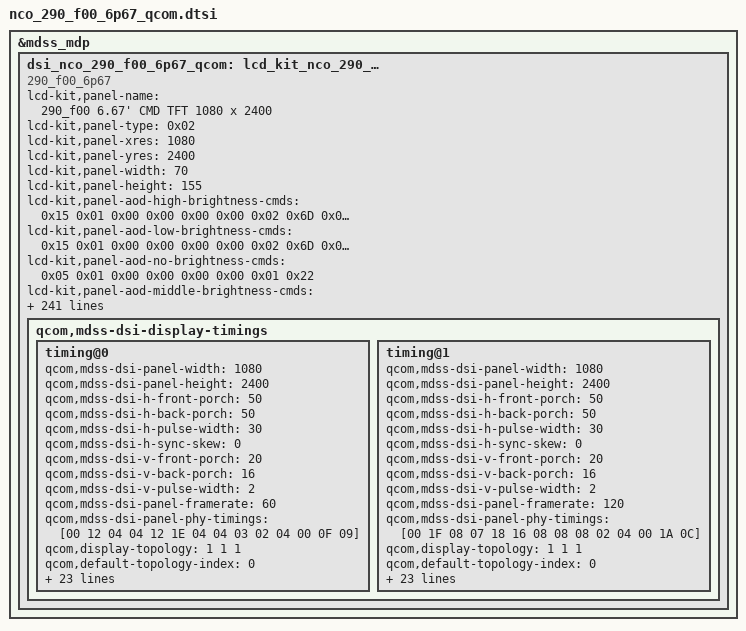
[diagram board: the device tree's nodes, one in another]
/* Copyright (c) 2013, The Linux Foundation. All rights reserved.
 *
 * This program is free software; you can redistribute it and/or modify
 * it under the terms of the GNU General Public License version 2 and
 * only version 2 as published by the Free Software Foundation.
 *
 * This program is distributed in the hope that it will be useful,
 * but WITHOUT ANY WARRANTY; without even the implied warranty of
 * MERCHANTABILITY or FITNESS FOR A PARTICULAR PURPOSE.  See the
 * GNU General Public License for more details.
 */

/*-------------------------------------------------------------------------
 * This file is autogenerated file using gcdb parser. Please do not edit it.
 * Update input XML file to add a new entry or update variable in this file
 * VERSION = 1.1
 *-----------------------------------------------------------------------*/
&mdss_mdp {
	dsi_nco_290_f00_6p67_qcom: lcd_kit_nco_290_f00_6p67_qcom {
		compatible = "290_f00_6p67";
		lcd-kit,panel-name = "290_f00 6.67' CMD TFT 1080 x 2400";
		lcd-kit,panel-type = <0x02>;
		lcd-kit,panel-xres = <1080>;
		lcd-kit,panel-yres = <2400>;
		lcd-kit,panel-width = <70>;
		lcd-kit,panel-height = <155>;
		lcd-kit,panel-aod-high-brightness-cmds = <0x15 0x01 0x00 0x00 0x00 0x00 0x02 0x6D 0x00
		0x05 0x01 0x00 0x00 0x00 0x00 0x01 0x13>;
		lcd-kit,panel-aod-low-brightness-cmds = <0x15 0x01 0x00 0x00 0x00 0x00 0x02 0x6D 0x02
		0x05 0x01 0x00 0x00 0x00 0x00 0x01 0x13>;
		lcd-kit,panel-aod-no-brightness-cmds = <0x05 0x01 0x00 0x00 0x00 0x00 0x01 0x22>;
		lcd-kit,panel-aod-middle-brightness-cmds = <0x15 0x01 0x00 0x00 0x00 0x00 0x02 0x6D 0x01
		0x05 0x01 0x00 0x00 0x00 0x00 0x01 0x13>;
		lcd-kit,pcd-check-reg-cmds = <0x82>;
		lcd-kit,check-reg-on-cmds = <0x06 0x01 0x00 0x00 0x0a 0x00 0x01 0x0a>;
		lcd-kit,check-reg-on-value = <0x9c>;
		lcd-kit,check-aod-reg-on-cmds = <0x06 0x01 0x00 0x00 0x0a 0x00 0x01 0x0a>;
		lcd-kit,check-aod-reg-on-value = <0xdc>;
		lcd-kit,check-reg-off-cmds = <0x06 0x01 0x00 0x00 0x0a 0x00 0x01 0x0a>;
		lcd-kit,check-reg-off-value = <0x08>;
		lcd-kit,check-reg-on-cmds-state = "dsi_lp_mode";
		lcd-kit,check-aod-reg-on-cmds-state = "dsi_lp_mode";
		lcd-kit,check-reg-off-cmds-state = "dsi_lp_mode";
		lcd-kit,pcd-check-reg-value = <0x82>;
		lcd-kit,pcd-errflag-check-support = <0>;
		lcd-kit,checksum-enable-cmds = <0x39 0x01 0x00 0x00 0x00 0x00 0x03 0xFF 0x5A 0x80
		0x15 0x01 0x00 0x00 0x00 0x00 0x02 0xFC 0x11>;
		lcd-kit,checksum-enable-cmds-state = "dsi_lp_mode";
		lcd-kit,checksum-disable-cmds = <0x39 0x01 0x00 0x00 0x00 0x00 0x03 0xFF 0x5A 0x80
		0x15 0x01 0x00 0x00 0x00 0x00 0x02 0xFC 0x00>;
		lcd-kit,checksum-disable-cmds-state = "dsi_lp_mode";
		lcd-kit,checksum-cmds = <0x39 0x01 0x00 0x00 0x00 0x00 0x03 0xFF 0x5A 0x80
		0x15 0x01 0x00 0x00 0x00 0x00 0x02 0x65 0x01
		0x14 0x01 0x00 0x00 0x00 0x00 0x08 0xFC 0x00 0x00 0x00 0x00 0x00 0x00 0x00>;
		lcd-kit,checksum-cmds-state = "dsi_lp_mode";
		lcd-kit,checksum-value = <0xc6 0xa1 0x3f 0x1d 0xc6 0x47 0x89 0x3a
		0x43 0x61 0xc0 0x9a 0xc3 0xe4 0x29 0xf8
		0x6c 0xbb 0x14 0x70 0xbf 0xc9 0x49 0x5c>;
		lcd-kit,hor-line-cmds = <0x15 0x01 0x00 0x00 0x00 0x00 0x02 0x6C 0x01
		0x39 0x01 0x00 0x00 0x00 0x00 0x03 0xF0 0xAA 0x16
		0x39 0x01 0x00 0x00 0x00 0x00 0x05 0xB1 0x24 0x25 0x25 0x0A
		0x39 0x01 0x00 0x00 0x00 0x00 0x05 0xB6 0x24 0x25 0x25 0x0A>;
		lcd-kit,hor-line-cmds-state = "dsi_lp_mode";
		lcd-kit,pcd-read-cmds = <0x39 0x01 0x00 0x00 0x00 0x00 0x03 0xF0 0xAA 0x12
		0x39 0x01 0x00 0x00 0x0a 0x00 0x05 0xD0 0x8D 0x01 0x01 0x00
		0x15 0x01 0x00 0x00 0x00 0x00 0x02 0x65 0x03
		0x06 0x01 0x00 0x00 0x00 0x00 0x01 0xD0>;
		lcd-kit,pcd-read-cmds-state  = "dsi_lp_mode";
		lcd-kit,vtc-line-cmds = <0x39 0x01 0x00 0x00 0x00 0x00 0x03 0x51 0x00 0x00
		0x39 0x01 0x00 0x00 0x00 0x00 0x03 0xF0 0xAA 0x10
		0x15 0x01 0x00 0x00 0x00 0x00 0x02 0xC3 0x11
		0x39 0x01 0x00 0x00 0x00 0x00 0x03 0xF0 0xAA 0x12
		0x15 0x01 0x00 0x00 0x00 0x00 0x02 0xCF 0x00
		0x39 0x01 0x00 0x00 0x00 0x00 0x0F 0xB6 0x00 0x3F 0x00 0x3F 0x00 0x3F 0x00 0x3F 0x00 0x3F 0x00 0x3F 0x00 0x3F
		0x39 0x01 0x00 0x00 0x00 0x00 0x03 0xF0 0xAA 0x13
		0x15 0x01 0x00 0x00 0x00 0x00 0x02 0x65 0x01
		0x15 0x01 0x00 0x00 0x00 0x00 0x02 0xC7 0x12
		0x15 0x01 0x00 0x00 0x00 0x00 0x02 0x65 0x01
		0x15 0x01 0x00 0x00 0x00 0x00 0x02 0xCC 0x12>;
		lcd-kit,vtc-line-cmds-state  = "dsi_lp_mode";
		lcd-kit,ddic-lv-det-enter1-cmds = <0x39 0x01 0x00 0x00 0x00 0x00 0x03 0xF0 0xAA 0x12
		0x39 0x01 0x00 0x00 0x00 0x00 0x05 0xC7 0x2F 0x43 0x32 0x44>;
		lcd-kit,ddic-lv-det-enter1-cmds-state  = "dsi_lp_mode";
		lcd-kit,ddic-lv-det-enter2-cmds = <0x39 0x01 0x00 0x00 0x00 0x00 0x03 0xF0 0xAA 0x12
		0x39 0x01 0x00 0x00 0x00 0x00 0x05 0xC7 0x2F 0x43 0x32 0x44>;
		lcd-kit,ddic-lv-det-enter2-cmds-state  = "dsi_lp_mode";
		lcd-kit,ddic-lv-det-enter3-cmds = <0x39 0x01 0x00 0x00 0x00 0x00 0x03 0xF0 0xAA 0x12
		0x39 0x01 0x00 0x00 0x00 0x00 0x05 0xC7 0x2F 0x43 0x32 0x44>;
		lcd-kit,ddic-lv-det-enter3-cmds-state  = "dsi_lp_mode";
		lcd-kit,ddic-lv-det-enter4-cmds = <0x39 0x01 0x00 0x00 0x00 0x00 0x03 0xF0 0xAA 0x12
		0x39 0x01 0x00 0x00 0x00 0x00 0x05 0xC7 0x2F 0x43 0x32 0x44>;
		lcd-kit,ddic-lv-det-enter4-cmds-state  = "dsi_lp_mode";
		lcd-kit,ddic-lv-det-rd1-cmds = <0x06 0x01 0x00 0x00 0x00 0x00 0x01 0x0a>;
		lcd-kit,ddic-lv-det-rd1-cmds-state  = "dsi_lp_mode";
		lcd-kit,ddic-lv-det-rd2-cmds = <0x06 0x01 0x00 0x00 0x00 0x00 0x01 0x0a>;
		lcd-kit,ddic-lv-det-rd2-cmds-state  = "dsi_lp_mode";
		lcd-kit,ddic-lv-det-rd3-cmds = <0x06 0x01 0x00 0x00 0x00 0x00 0x01 0x0a>;
		lcd-kit,ddic-lv-det-rd3-cmds-state  = "dsi_lp_mode";
		lcd-kit,ddic-lv-det-rd4-cmds = <0x06 0x01 0x00 0x00 0x00 0x00 0x01 0x0a>;
		lcd-kit,ddic-lv-det-rd4-cmds-state  = "dsi_lp_mode";
		lcd-kit,ddic-lv-det-value1 = <0x9c>;
		lcd-kit,ddic-lv-det-value2 = <0x9c>;
		lcd-kit,ddic-lv-det-value3 = <0x9c>;
		lcd-kit,ddic-lv-det-value4 = <0x9c>;
		lcd-kit,bl-after-frame = <0>;
		lcd-kit,cmd-async-support = <0>;
		lcd-kit,ap-aod-support = <1>;
		lcd-kit,mask-delay-time-before-fp = <33334>;
		lcd-kit,mask-delay-time-after-fp = <0>;
		lcd-kit,left-time-to-te-us = <26500>;
		lcd-kit,right-time-to-te-us = <27000>;
		lcd-kit,te-interval-time-us = <16667>;
		lcd-kit,dc-delay-support = <1>;
		lcd-kit,dc-left-time-to-te-us = <9000>;
		lcd-kit,dc-right-time-to-te-us = <10000>;
		lcd-kit,dc-delay-time-before-fp = <0>;
		lcd-kit,dc-delay-time-after-fp = <0>;
		lcd-kit,oneside-mode-support = <0>;
		lcd-kit,color-aod-detect-support = <0>;
		lcd-kit,elvdd-detect-support = <0>;
		lcd-kit,elvdd-detect-type = <2>;
		lcd-kit,elvdd-detect-value = <1>;
		lcd-kit,elvdd-delay = <50>;
		lcd-kit,elvdd-detect-gpio = <104>;
		lcd-kit,check-reg-on-support = <0>;
		lcd-kit,check-reg-on-support-dsm-report = <0>;
		lcd-kit,check-aod-reg-on-support = <0>;
		lcd-kit,check-aod-reg-on-support-dsm-report = <0>;
		lcd-kit,check-reg-off-support = <0>;
		lcd-kit,check-reg-off-support-dsm-report = <0>;
		lcd-kit,checksum-support = <1>;
		lcd-kit,pcd-cmds-support = <1>;
		lcd-kit,pcd-check-reg-value-compare-mode = <1>;
		lcd-kit,vtc-line-support = <1>;
		lcd-kit,ddic-lv-det-support = <1>;
		lcd-kit,hor-line-support = <1>;
		lcd-kit,hor-line-duration = <600>;
		lcd-kit,vtc-line-no-reset = <1>;
		qcom,mdss-dsi-panel-type = "dsi_cmd_mode";
		qcom,mdss-pan-physical-width-dimension = <70>;
		qcom,mdss-pan-physical-height-dimension = <155>;
		qcom,dsi-ctrl-num = <0>;
		qcom,dsi-phy-num = <0>;
		qcom,panel-supply-entries = <&dsi_panel_pwr_supply>;
		qcom,mdss-dsi-virtual-channel-id = <0>;
		qcom,mdss-dsi-h-sync-pulse = <0>;
		qcom,mdss-dsi-bllp-eof-power-mode;
		qcom,mdss-dsi-bllp-power-mode;
		qcom,mdss-dsi-dma-schedule-line = <1>;
		qcom,mdss-dsi-bpp = <24>;
		qcom,mdss-dsi-color-order = "rgb_swap_rgb";
		qcom,mdss-dsi-underflow-color = <0xff>;
		qcom,mdss-dsi-border-color = <0>;
		qcom,mdss-dsi-traffic-mode = "burst_mode";
		qcom,mdss-dsi-lane-map = "lane_map_0123";
		qcom,mdss-dsi-lane-0-state;
		qcom,mdss-dsi-lane-1-state;
		qcom,mdss-dsi-lane-2-state;
		qcom,mdss-dsi-lane-3-state;
		qcom,mdss-dsi-mdp-trigger = "none";
		qcom,mdss-dsi-dma-trigger = "trigger_sw";
		qcom,mdss-dsi-te-pin-select = <1>;
		qcom,mdss-dsi-wr-mem-start = <0x2c>;
		qcom,mdss-dsi-wr-mem-continue = <0x3c>;
		qcom,mdss-dsi-te-dcs-command = <1>;
		qcom,mdss-dsi-te-check-enable;
		qcom,mdss-dsi-te-using-te-pin;
		qcom,dsi-panel-gpio-address = <0x0F100000 0x1000>;
		qcom,dsi-panel-gpio-pins = <12 93 80>;
		qcom,dsi-panel-gpio-names = "reg-gpio", "reset-gpio", "platform-te-gpio";
		qcom,mdss-dsi-t-clk-post = <0>;
		qcom,mdss-dsi-t-clk-pre = <0>;
		qcom,dsi-select-clocks = "mux_byte_clk0", "mux_pixel_clk0";
		qcom,mdss-dsi-stream = <0>;
		lcd-kit,check-thread-support = <0>;
		lcd-kit,check-time-period = <5000>;
		lcd-kit,check-fold-support = <0>;
		lcd-kit,fold-low-power-support = <0>;
		lcd-kit,fold-height = <0>;
		lcd-kit,unfold-height = <0>;
		lcd-kit,power-support = <0>;
		lcd-kit,three-stage-poweron = <1>;
		lcd-kit,fold-lp-time = <0>;
		lcd-kit,fold-nolp-time = <0>;
		qcom,sublinks-count = <2>;
		qcom,lanes-per-sublink = <2>;
		qcom,mdss-dsi-panel-hdr-color-primaries = <14500 15500 32000 17000 15500 30000 8000 3000>;
		qcom,mdss-dsi-panel-peak-brightness = <4200000>;
		qcom,mdss-dsi-panel-blackness-level = <3230>;
		qcom,dynamic-mode-switch-enabled;
		qcom,dynamic-mode-switch-type = "dynamic-resolution-switch-immediate";
		qcom,mdss-dsi-bl-pmic-control-type = "bl_ctrl_dcs";
		qcom,mdss-dsi-bl-min-level = <1>;
		qcom,mdss-dsi-bl-max-level = <10000>;
		qcom,esd-check-enabled;
		qcom,mdss-dsi-panel-status-command = [06 01 00 00 00 00 02 68 00
			06 01 00 00 00 00 01 0A
			39 01 00 00 00 00 03 FF 5A 80
			15 01 00 00 00 00 02 65 37
			06 01 00 00 00 00 03 F5 00 00
			39 01 00 00 00 00 03 F0 AA 10
			06 01 00 00 00 00 02 ED 00
			39 01 00 00 00 00 03 FF 5A 80
			06 01 00 00 00 00 09 FE 00 00 00 00 00 00 00 00];
		qcom,mdss-dsi-panel-status-command-state = "dsi_lp_mode";
		qcom,mdss-dsi-panel-status-check-mode = "reg_read";
		qcom,mdss-dsi-panel-status-read-length = <2 1 0 0 3 0 2 0 9>;
		qcom,mdss-dsi-panel-status-value = <0x00 0x00>,<0x9C>,<0x00 0x00 0x00>,<0x00 0x30>,<0x00 0x00 0x00 0x00 0x00 0x00 0x00 0x00 0x00>;
		lcd-kit,power-on-stage = <2 1 3
				1 1 3
				9 1 12>;
		lcd-kit,lp-on-stage = <5 1 5
				5 0 2
				5 1 30
				7 1 0
				6 1 0
				8 1 0>;
		lcd-kit,lp-off-stage = <0 0 0>;
		lcd-kit,power-off-stage = <7 0 0
				6 0 0
				8 0 0
				5 0 2
				9 0 2
				1 0 2
				2 0 1>;
		lcd-kit,only-power-off-stage = <0 0 0>;
		lcd-kit,pt-support = <1>;
		lcd-kit,panel-on-always-reset = <0>;
		lcd-kit,lcd-vci = <1 13 3000000 3000000 3000000 10000 80>;
		lcd-kit,lcd-iovcc = <1 12 1800000 1800000 1800000 60700 80>;
		lcd-kit,lcd-vdd = <1 16 1250000 1250000 1250000 30000 80>;
		lcd-kit,lcd-reset = <2 93 0>;
		lcd-kit,lcd-vci-name = "vdd";
		lcd-kit,lcd-iovcc-name = "vddio";
		lcd-kit,lcd-vdd-name = "ddic";
		lcd-kit,project-id-support = <0>;
		lcd-kit,default-project-id = "B2359S2920";
		lcd-kit,sn-code-support = <1>;
		lcd-kit,oem-info-support = <1>;
		lcd-kit,oem-barcode-2d-support = <1>;
		lcd-kit,oem-barcode-2d-num-offset = <0>;
		lcd-kit,barcode-2d-cmds = <0x39 0x01 0x00 0x00 0x00 0x00 0x03 0xF0 0xAA 0x10
		0x14 0x01 0x00 0x00 0x00 0x00 0x15 0xC8 0x00 0x00 0x00 0x00 0x00 0x00 0x00 0x00 0x00 0x00 0x00 0x00 0x00 0x00 0x00 0x00 0x00 0x00 0x00 0x00>;
		lcd-kit,barcode-2d-cmds-state = "dsi_lp_mode";
		lcd-kit,panel-getblmaxnit-type = <0>;
		lcd-kit,panel-blmaxnit-min-value = <400>;
		lcd-kit,inversion-support = <0>;
		lcd-kit,panel-gpio-offset = <336>;
		lcd-kit,finger-unlock-state-support = <0>;
		lcd-kit,finger-handle-esd-support = <1>;
		lcd-kit,esd-reg-te-check = <0>;
		lcd-kit,dump-support = <0>;
		lcd-kit,underflow-support = <1>;
		lcd-kit,panel-bl-max-nit = <450>;
		lcd-kit,panel-bl-min = <3>;
		lcd-kit,panel-bl-max = <10000>;
		lcd-kit,panel-bl-def = <2047>;
		lcd-kit,check-reg-support = <0>;
		lcd-kit,thp-proximity-support = <0>;
		lcd-kit,proximity-reset-delay-min = <65>;
		lcd-kit,backlight-cmds = <0x39 0x01 0x00 0x00 0x00 0x00 0x03 0x51 0x00 0x00>;
		lcd-kit,backlight-cmds-state = "dsi_lp_mode";
		lcd-kit,backlight-order = <0>;
		lcd-kit,backlight-need-sync = <0>;
		lcd-kit,fps-support = <1>;
		lcd-kit,default-fps = <60>;
		lcd-kit,panel-support-fps-list = <60 120>;
		lcd-kit,fps-60-cmd = "vndservice call display.qservice 25 i32 0 i32 0";
		lcd-kit,fps-90-cmd = "vndservice call display.qservice 25 i32 2 i32 0";
		lcd-kit,fps-120-cmd = "vndservice call display.qservice 25 i32 1 i32 0";
		qcom,mdss-dsi-display-timings {
			timing@0 {
				qcom,mdss-dsi-panel-width = <1080>;
				qcom,mdss-dsi-panel-height = <2400>;
				qcom,mdss-dsi-h-front-porch = <50>;
				qcom,mdss-dsi-h-back-porch = <50>;
				qcom,mdss-dsi-h-pulse-width = <30>;
				qcom,mdss-dsi-h-sync-skew = <0>;
				qcom,mdss-dsi-v-front-porch = <20>;
				qcom,mdss-dsi-v-back-porch = <16>;
				qcom,mdss-dsi-v-pulse-width = <2>;
				qcom,mdss-dsi-panel-framerate = <60>;
				qcom,mdss-dsi-panel-phy-timings= [00 12 04 04 12 1E 04
			04 03 02 04 00 0F 09];
				qcom,display-topology  = <1 1 1>;
				qcom,default-topology-index  = <0>;
				qcom,mdss-dsi-on-command = [15 01 00 00 00 00 02 03 01
		15 01 00 00 00 00 02 35 00
		15 01 00 00 00 00 02 53 20
		15 01 00 00 00 00 02 59 09
		15 01 00 00 00 00 02 6C 00
		15 01 00 00 00 00 02 6F 02
		39 01 00 00 00 00 15 70 11 00 00 AB 30 80 09 60 04 38 00 28 04 38 04 38 02 00 03 1C
		15 01 00 00 00 00 02 65 14
		39 01 00 00 00 00 15 70 00 20 05 2D 00 0F 00 0C 02 77 01 46 18 00 10 F0 07 10 20 00
		15 01 00 00 00 00 02 65 28
		39 01 00 00 00 00 15 70 06 0F 0F 33 0E 1C 2A 38 46 54 62 69 70 77 79 7B 7D 7E 02 02
		15 01 00 00 00 00 02 65 3C
		39 01 00 00 00 00 15 70 22 00 2A 40 2A BE 3A FC 3A FA 3A F8 3B 38 3B 78 3B B6 4B B6
		15 01 00 00 00 00 02 65 50
		39 01 00 00 00 00 0F 70 4B F4 4B F4 6C 34 84 74 00 00 00 00 00 00
		39 01 00 00 00 00 03 F0 AA 10
		15 01 00 00 00 00 02 B3 C7
		15 01 00 00 00 00 02 B6 00
		39 01 00 00 00 00 15 D0 84 15 50 14 20 00 29 4B 17 4F 22 00 4B 29 00 00 00 00 05 05
		15 01 00 00 00 00 02 65 01
		39 01 00 00 00 00 04 EB 03 30 01
		39 01 00 00 00 00 03 F0 AA 12
		39 01 00 00 00 00 05 C7 2E 73 32 74
		39 01 00 00 00 00 03 F0 AA 14
		39 01 00 00 00 00 03 B2 03 33
		39 01 00 00 00 00 0D B4 0A 49 00 00 0A 49 00 00 0A 49 00 00
		39 01 00 00 00 00 0A B5 00 18 18 18 18 18 18 06 01
		39 01 00 00 00 00 07 B9 00 00 0A 18 18 18
		39 01 00 00 00 00 0D BC 10 00 00 0A 11 18 68 18 68 18 68 00
		39 01 00 00 00 00 0D BE 10 10 00 0A 22 18 45 18 45 18 45 00
		39 01 00 00 00 00 03 F0 AA 15
		15 01 00 00 00 00 02 BD 22
		39 01 00 00 00 00 03 FF 5A 81
		15 01 00 00 00 00 02 65 05
		15 01 00 00 00 00 02 F3 0F
		15 01 00 00 00 00 02 65 01
		15 01 00 00 00 00 02 F4 9A
		39 01 00 00 00 00 03 FF 5A 80
		15 01 00 00 00 00 02 65 13
		15 01 00 00 00 00 02 FD 01
		39 01 00 00 00 00 03 FF 5A 82
		15 01 00 00 00 00 02 F9 00
		39 01 00 00 00 00 03 FF 5A 83
		15 01 00 00 00 00 02 65 04
		15 01 00 00 00 00 02 F8 00
		39 01 00 00 00 00 03 F0 AA 00
		39 01 00 00 00 00 03 FF 5A 00
		05 01 00 00 78 00 01 11
		05 01 00 00 00 00 01 29
		39 01 00 00 00 00 03 F0 AA 10
		15 01 00 00 00 00 02 65 03
		15 01 00 00 0A 00 02 EB 09];
				qcom,mdss-dsi-on-command-state = "dsi_lp_mode";
				qcom,mdss-dsi-off-command = [05 01 00 00 0a 00 01 28
		05 01 00 00 78 00 01 10];
				qcom,mdss-dsi-off-command-state = "dsi_lp_mode";
				qcom,compression-mode = "dsc";
				qcom,mdss-dsc-slice-height = <40>;
				qcom,mdss-dsc-slice-width = <1080>;
				qcom,mdss-dsc-slice-per-pkt = <1>;
				qcom,mdss-dsc-bit-per-component = <10>;
				qcom,mdss-dsc-bit-per-pixel = <8>;
				qcom,mdss-dsc-block-prediction-enable;
				qcom,mdss-dsi-timing-switch-command = [15 01 00 00 11 00 02 6C 00];
				qcom,mdss-dsi-timing-switch-command-state = "dsi_lp_mode";
				qcom,mdss-dsi-lp1-command = [05 01 00 00 00 00 01 22
		05 01 00 00 00 00 01 39
		39 01 00 00 00 00 03 F0 AA 10
		15 01 00 00 00 00 02 B3 C6];
				qcom,mdss-dsi-lp1-command-state = "dsi_lp_mode";
				qcom,mdss-dsi-nolp-command = [05 01 00 00 00 00 01 22
		05 01 00 00 00 00 01 38
		39 01 00 00 00 00 03 F0 AA 10
		15 01 00 00 32 00 02 B3 C7
		05 01 00 00 00 00 01 13];
				qcom,mdss-dsi-nolp-command-state = "dsi_lp_mode";
			};
			timing@1 {
				qcom,mdss-dsi-panel-width = <1080>;
				qcom,mdss-dsi-panel-height = <2400>;
				qcom,mdss-dsi-h-front-porch = <50>;
				qcom,mdss-dsi-h-back-porch = <50>;
				qcom,mdss-dsi-h-pulse-width = <30>;
				qcom,mdss-dsi-h-sync-skew = <0>;
				qcom,mdss-dsi-v-front-porch = <20>;
				qcom,mdss-dsi-v-back-porch = <16>;
				qcom,mdss-dsi-v-pulse-width = <2>;
				qcom,mdss-dsi-panel-framerate = <120>;
				qcom,mdss-dsi-panel-phy-timings= [00 1F 08 07 18 16 08
			08 08 02 04 00 1A 0C];
				qcom,display-topology  = <1 1 1>;
				qcom,default-topology-index  = <0>;
				qcom,mdss-dsi-on-command = [15 01 00 00 00 00 02 03 01
		15 01 00 00 00 00 02 35 00
		15 01 00 00 00 00 02 53 20
		15 01 00 00 00 00 02 59 09
		15 01 00 00 00 00 02 6C 01
		15 01 00 00 00 00 02 6F 02
		39 01 00 00 00 00 15 70 11 00 00 AB 30 80 09 60 04 38 00 28 04 38 04 38 02 00 03 1C
		15 01 00 00 00 00 02 65 14
		39 01 00 00 00 00 15 70 00 20 05 2D 00 0F 00 0C 02 77 01 46 18 00 10 F0 07 10 20 00
		15 01 00 00 00 00 02 65 28
		39 01 00 00 00 00 15 70 06 0F 0F 33 0E 1C 2A 38 46 54 62 69 70 77 79 7B 7D 7E 02 02
		15 01 00 00 00 00 02 65 3C
		39 01 00 00 00 00 15 70 22 00 2A 40 2A BE 3A FC 3A FA 3A F8 3B 38 3B 78 3B B6 4B B6
		15 01 00 00 00 00 02 65 50
		39 01 00 00 00 00 0F 70 4B F4 4B F4 6C 34 84 74 00 00 00 00 00 00
		39 01 00 00 00 00 03 F0 AA 10
		15 01 00 00 00 00 02 B3 C7
		15 01 00 00 00 00 02 B6 00
		39 01 00 00 00 00 15 D0 84 15 50 14 20 00 29 4B 17 4F 22 00 4B 29 00 00 00 00 05 05
		15 01 00 00 00 00 02 65 01
		39 01 00 00 00 00 04 EB 03 30 01
		39 01 00 00 00 00 03 F0 AA 12
		39 01 00 00 00 00 05 C7 2E 73 32 74
		39 01 00 00 00 00 03 F0 AA 14
		39 01 00 00 00 00 03 B2 03 33
		39 01 00 00 00 00 0D B4 0A 49 00 00 0A 49 00 00 0A 49 00 00
		39 01 00 00 00 00 0A B5 00 18 18 18 18 18 18 06 01
		39 01 00 00 00 00 07 B9 00 00 0A 18 18 18
		39 01 00 00 00 00 0D BC 10 00 00 0A 11 18 68 18 68 18 68 00
		39 01 00 00 00 00 0D BE 10 10 00 0A 22 18 45 18 45 18 45 00
		39 01 00 00 00 00 03 F0 AA 15
		15 01 00 00 00 00 02 BD 22
		39 01 00 00 00 00 03 FF 5A 81
		15 01 00 00 00 00 02 65 05
		15 01 00 00 00 00 02 F3 0F
		15 01 00 00 00 00 02 65 01
		15 01 00 00 00 00 02 F4 9A
		39 01 00 00 00 00 03 FF 5A 80
		15 01 00 00 00 00 02 65 13
		15 01 00 00 00 00 02 FD 01
		39 01 00 00 00 00 03 FF 5A 82
		15 01 00 00 00 00 02 F9 00
		39 01 00 00 00 00 03 FF 5A 83
		15 01 00 00 00 00 02 65 04
		15 01 00 00 00 00 02 F8 00
		39 01 00 00 00 00 03 F0 AA 00
		39 01 00 00 00 00 03 FF 5A 00
		05 01 00 00 78 00 01 11
		05 01 00 00 00 00 01 29
		39 01 00 00 00 00 03 F0 AA 10
		15 01 00 00 00 00 02 65 03
		15 01 00 00 0A 00 02 EB 09];
				qcom,mdss-dsi-on-command-state = "dsi_lp_mode";
				qcom,mdss-dsi-off-command = [05 01 00 00 0a 00 01 28
		05 01 00 00 78 00 01 10];
				qcom,mdss-dsi-off-command-state = "dsi_lp_mode";
				qcom,compression-mode = "dsc";
				qcom,mdss-dsc-slice-height = <40>;
				qcom,mdss-dsc-slice-width = <1080>;
				qcom,mdss-dsc-slice-per-pkt = <1>;
				qcom,mdss-dsc-bit-per-component = <10>;
				qcom,mdss-dsc-bit-per-pixel = <8>;
				qcom,mdss-dsc-block-prediction-enable;
				qcom,mdss-dsi-timing-switch-command = [15 01 00 00 00 00 02 6C 01];
				qcom,mdss-dsi-timing-switch-command-state = "dsi_lp_mode";
				qcom,mdss-dsi-lp1-command = [15 01 00 00 00 00 02 6C 00
		05 01 00 00 00 00 01 22
		05 01 00 00 00 00 01 39
		39 01 00 00 00 00 03 F0 AA 10
		15 01 00 00 00 00 02 B3 C6];
				qcom,mdss-dsi-lp1-command-state = "dsi_lp_mode";
				qcom,mdss-dsi-nolp-command = [15 01 00 00 00 00 02 6C 01
		05 01 00 00 00 00 01 22
		05 01 00 00 00 00 01 38
		39 01 00 00 00 00 03 F0 AA 10
		15 01 00 00 32 00 02 B3 C7
		05 01 00 00 00 00 01 13];
				qcom,mdss-dsi-nolp-command-state = "dsi_lp_mode";
			};
		};
    };
};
